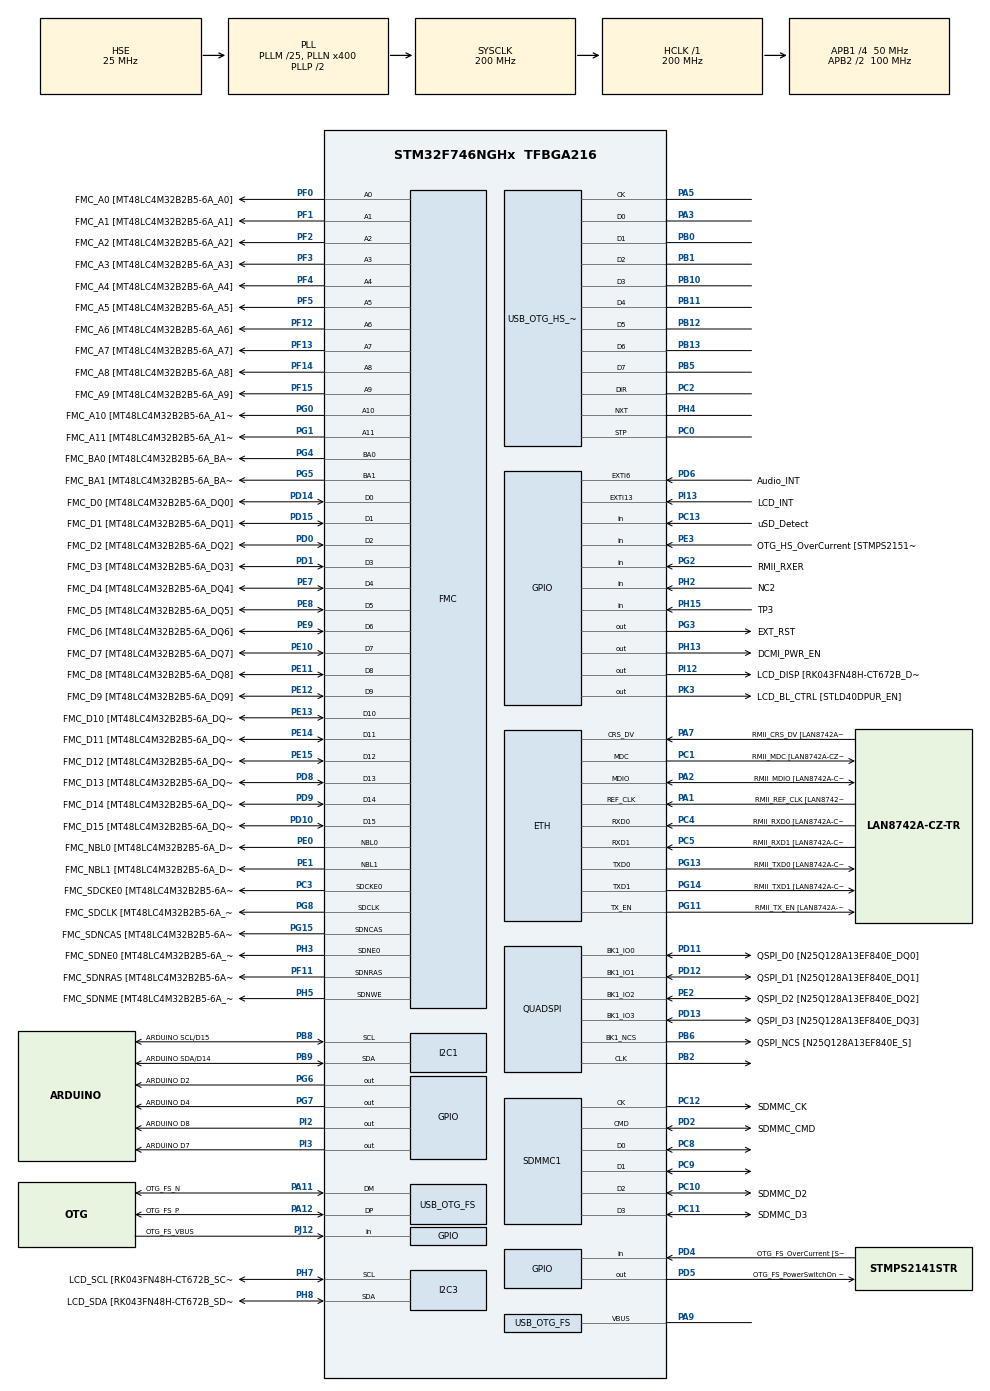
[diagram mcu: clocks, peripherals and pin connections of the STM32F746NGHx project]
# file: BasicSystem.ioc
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CORTEX_M7.ART_ACCLERATOR_ENABLE=1
CORTEX_M7.AccessPermission-Cortex_Memory_Protection_Unit_Region0_Settings=MPU_REGION_FULL_ACCESS
CORTEX_M7.AccessPermission-Cortex_Memory_Protection_Unit_Region1_Settings=MPU_REGION_FULL_ACCESS
CORTEX_M7.BaseAddress-Cortex_Memory_Protection_Unit_Region0_Settings=0x90000000
CORTEX_M7.BaseAddress-Cortex_Memory_Protection_Unit_Region1_Settings=0x90000000
CORTEX_M7.CPU_DCache=Enabled
CORTEX_M7.CPU_ICache=Enabled
CORTEX_M7.Enable-Cortex_Memory_Protection_Unit_Region0_Settings=MPU_REGION_ENABLE
CORTEX_M7.Enable-Cortex_Memory_Protection_Unit_Region1_Settings=MPU_REGION_ENABLE
CORTEX_M7.IsCacheable-Cortex_Memory_Protection_Unit_Region1_Settings=MPU_ACCESS_CACHEABLE
CORTEX_M7.MPU_Control=MPU_PRIVILEGED_DEFAULT
CORTEX_M7.PREFETCH_ENABLE=1
CORTEX_M7.Size-Cortex_Memory_Protection_Unit_Region0_Settings=MPU_REGION_SIZE_256MB
CORTEX_M7.Size-Cortex_Memory_Protection_Unit_Region1_Settings=MPU_REGION_SIZE_16MB
Dma.Request0=SDMMC1_RX
Dma.Request1=SDMMC1_TX
Dma.SDMMC1_RX.0.Direction=DMA_PERIPH_TO_MEMORY
Dma.SDMMC1_RX.0.FIFOMode=DMA_FIFOMODE_ENABLE
Dma.SDMMC1_RX.0.FIFOThreshold=DMA_FIFO_THRESHOLD_FULL
Dma.SDMMC1_RX.0.Instance=DMA2_Stream3
Dma.SDMMC1_RX.0.MemBurst=DMA_MBURST_INC4
Dma.SDMMC1_RX.0.MemDataAlignment=DMA_MDATAALIGN_WORD
Dma.SDMMC1_RX.0.MemInc=DMA_MINC_ENABLE
Dma.SDMMC1_RX.0.Mode=DMA_PFCTRL
Dma.SDMMC1_RX.0.PeriphBurst=DMA_PBURST_INC4
Dma.SDMMC1_RX.0.PeriphDataAlignment=DMA_PDATAALIGN_WORD
Dma.SDMMC1_RX.0.PeriphInc=DMA_PINC_DISABLE
Dma.SDMMC1_RX.0.Priority=DMA_PRIORITY_LOW
Dma.SDMMC1_TX.1.Direction=DMA_MEMORY_TO_PERIPH
Dma.SDMMC1_TX.1.FIFOMode=DMA_FIFOMODE_ENABLE
Dma.SDMMC1_TX.1.FIFOThreshold=DMA_FIFO_THRESHOLD_FULL
Dma.SDMMC1_TX.1.Instance=DMA2_Stream6
Dma.SDMMC1_TX.1.MemBurst=DMA_MBURST_INC4
Dma.SDMMC1_TX.1.MemDataAlignment=DMA_MDATAALIGN_WORD
Dma.SDMMC1_TX.1.MemInc=DMA_MINC_ENABLE
Dma.SDMMC1_TX.1.Mode=DMA_PFCTRL
Dma.SDMMC1_TX.1.PeriphBurst=DMA_PBURST_INC4
Dma.SDMMC1_TX.1.PeriphDataAlignment=DMA_PDATAALIGN_WORD
Dma.SDMMC1_TX.1.PeriphInc=DMA_PINC_DISABLE
Dma.SDMMC1_TX.1.Priority=DMA_PRIORITY_LOW
ETH.MediaInterface=ETH_MEDIA_INTERFACE_RMII
FATFS.BSP.number=1
FATFS0.BSP.STBoard=false
FATFS0.BSP.api=Unknown
FATFS0.BSP.i2caddr=0
FATFS0.BSP.instance=PC13
FATFS0.BSP.ip=GPIO
FATFS0.BSP.mode=Input
FATFS0.BSP.name=Detect_SDIO
FATFS0.BSP.solution=PC13
FMC.CASLatency1=FMC_SDRAM_CAS_LATENCY_3
FMC.ExitSelfRefreshDelay1=7
FMC.LoadToActiveDelay1=2
FMC.RCDDelay1=2
FMC.RPDelay1=2
FMC.RPDelay2=2
FMC.ReadBurst1=FMC_SDRAM_RBURST_ENABLE
FMC.ReadBurst2=FMC_SDRAM_RBURST_ENABLE
FMC.RowCycleDelay1=7
FMC.RowCycleDelay2=7
FMC.SDClockPeriod1=FMC_SDRAM_CLOCK_PERIOD_2
FMC.SDClockPeriod2=FMC_SDRAM_CLOCK_PERIOD_2
FMC.SelfRefreshTime1=4
FMC.WriteRecoveryTime1=3
FREERTOS.MEMORY_ALLOCATION=2
FREERTOS.Tasks01=defaultTaskHand,0,4096,StartDefaultTask,Default,NULL,Dynamic,NULL,NULL
FREERTOS.configCHECK_FOR_STACK_OVERFLOW=2
FREERTOS.configTOTAL_HEAP_SIZE=32768
FREERTOS.configUSE_APPLICATION_TASK_TAG=1
FREERTOS.configUSE_COUNTING_SEMAPHORES=1
FREERTOS.configUSE_IDLE_HOOK=1
FREERTOS.configUSE_MALLOC_FAILED_HOOK=1
FREERTOS.configUSE_RECURSIVE_MUTEXES=1
I2C1.Timing=0x00C0EAFF
I2C3.I2C_Rise_Time=0
I2C3.Speed=100
I2C3.Timing=0x00C0EAFF
LWIP.Version=v2.1.2_Cube
Mcu.Family=STM32F7
Mcu.Name=STM32F746NGHx
Mcu.Package=TFBGA216
NVIC.DMA2D_IRQn=true\:5\:0\:false\:false\:true\:true\:true\:true
NVIC.DMA2_Stream3_IRQn=true\:5\:0\:false\:false\:true\:true\:false\:true
NVIC.DMA2_Stream6_IRQn=true\:5\:0\:false\:false\:true\:true\:false\:true
NVIC.ETH_IRQn=true\:5\:0\:false\:false\:true\:true\:false\:true
NVIC.OTG_FS_IRQn=true\:5\:0\:false\:false\:true\:true\:false\:true
NVIC.OTG_HS_IRQn=true\:5\:0\:false\:false\:true\:true\:false\:true
NVIC.PriorityGroup=NVIC_PRIORITYGROUP_4
NVIC.SDMMC1_IRQn=true\:5\:0\:false\:false\:true\:true\:true\:true
NVIC.TIM6_DAC_IRQn=true\:0\:0\:false\:false\:true\:false\:false\:true
NVIC.TimeBase=TIM6_DAC_IRQn
NVIC.TimeBaseIP=TIM6
PA0/WKUP.GPIO_Label=ARDUINO A0
PA0/WKUP.GPIO_Mode=GPIO_MODE_ANALOG
PA0/WKUP.GPIO_PuPd=GPIO_NOPULL
PA0/WKUP.Signal=ADCx_IN0
PA1.GPIO_Label=RMII_REF_CLK [LAN8742A-CZ-TR_REFCLK0]
PA1.Mode=RMII
PA1.Signal=ETH_REF_CLK
PA10.GPIO_Label=OTG_FS_ID
PA10.Signal=USB_OTG_FS_ID
PA11.GPIO_Label=OTG_FS_N
PA11.GPIO_Speed=GPIO_SPEED_FREQ_VERY_HIGH
PA11.Mode=Host_Only
PA11.Signal=USB_OTG_FS_DM
PA12.GPIO_Label=OTG_FS_P
PA12.GPIO_Speed=GPIO_SPEED_FREQ_VERY_HIGH
PA12.Mode=Host_Only
PA12.Signal=USB_OTG_FS_DP
PA13.GPIO_Label=SWDIO
PA13.Mode=Serial_Wire
PA13.Signal=SYS_JTMS-SWDIO
PA14.GPIO_Label=SWCLK
PA14.Mode=Serial_Wire
PA14.Signal=SYS_JTCK-SWCLK
PA15.GPIO_Label=ARDUINO PWM/D9
PA15.GPIO_ModeDefaultPP=GPIO_MODE_AF_PP
PA15.GPIO_PuPd=GPIO_NOPULL
PA15.GPIO_Speed=GPIO_SPEED_FREQ_LOW
PA15.Signal=S_TIM2_CH1_ETR
PA2.GPIO_Label=RMII_MDIO [LAN8742A-CZ-TR_MDIO]
PA2.Mode=RMII
PA2.Signal=ETH_MDIO
PA3.GPIO_Mode=GPIO_MODE_AF_PP
PA3.GPIO_PuPd=GPIO_NOPULL
PA3.GPIO_Speed=GPIO_SPEED_FREQ_VERY_HIGH
PA3.Mode=Device_HS
PA3.Signal=USB_OTG_HS_ULPI_D0
PA4.GPIO_Label=DCMI_HSYNC
PA4.Signal=DCMI_HSYNC
PA5.GPIO_Mode=GPIO_MODE_AF_PP
PA5.GPIO_PuPd=GPIO_NOPULL
PA5.GPIO_Speed=GPIO_SPEED_FREQ_VERY_HIGH
PA5.Mode=Device_HS
PA5.Signal=USB_OTG_HS_ULPI_CK
PA6.Signal=DCMI_PIXCLK
PA7.GPIO_Label=RMII_CRS_DV [LAN8742A-CZ-TR_CRS_DV]
PA7.Mode=RMII
PA7.Signal=ETH_CRS_DV
PA8.GPIO_Label=ARDUINO PWM/D10
PA8.GPIO_ModeDefaultPP=GPIO_MODE_AF_PP
PA8.GPIO_PuPd=GPIO_NOPULL
PA8.GPIO_Speed=GPIO_SPEED_FREQ_LOW
PA8.Signal=S_TIM1_CH1
PA9.GPIO_PuPd=GPIO_NOPULL
PA9.Mode=Activate_VBUS
PA9.Signal=USB_OTG_FS_VBUS
PB0.GPIO_Mode=GPIO_MODE_AF_PP
PB0.GPIO_PuPd=GPIO_NOPULL
PB0.GPIO_Speed=GPIO_SPEED_FREQ_VERY_HIGH
PB0.Mode=Device_HS
PB0.Signal=USB_OTG_HS_ULPI_D1
PB1.GPIO_Mode=GPIO_MODE_AF_PP
PB1.GPIO_PuPd=GPIO_NOPULL
PB1.GPIO_Speed=GPIO_SPEED_FREQ_VERY_HIGH
PB1.Mode=Device_HS
PB1.Signal=USB_OTG_HS_ULPI_D2
PB10.GPIO_Mode=GPIO_MODE_AF_PP
PB10.GPIO_PuPd=GPIO_NOPULL
PB10.GPIO_Speed=GPIO_SPEED_FREQ_VERY_HIGH
PB10.Mode=Device_HS
PB10.Signal=USB_OTG_HS_ULPI_D3
PB11.GPIO_Mode=GPIO_MODE_AF_PP
PB11.GPIO_PuPd=GPIO_NOPULL
PB11.GPIO_Speed=GPIO_SPEED_FREQ_VERY_HIGH
PB11.Mode=Device_HS
PB11.Signal=USB_OTG_HS_ULPI_D4
PB12.GPIO_Mode=GPIO_MODE_AF_PP
PB12.GPIO_PuPd=GPIO_NOPULL
PB12.GPIO_Speed=GPIO_SPEED_FREQ_VERY_HIGH
PB12.Mode=Device_HS
PB12.Signal=USB_OTG_HS_ULPI_D5
PB13.GPIO_Mode=GPIO_MODE_AF_PP
PB13.GPIO_PuPd=GPIO_NOPULL
PB13.GPIO_Speed=GPIO_SPEED_FREQ_VERY_HIGH
PB13.Mode=Device_HS
PB13.Signal=USB_OTG_HS_ULPI_D6
PB14.GPIO_Label=ARDUINO MISO/D12
PB14.GPIO_Mode=GPIO_MODE_AF_PP
PB14.GPIO_PuPd=GPIO_NOPULL
PB14.GPIO_Speed=GPIO_SPEED_FREQ_LOW
PB14.Signal=SPI2_MISO
PB15.GPIO_Label=ARDUINO MOSI/PWM/D11
PB15.GPIO_Mode=GPIO_MODE_AF_PP
PB15.GPIO_PuPd=GPIO_NOPULL
PB15.GPIO_Speed=GPIO_SPEED_FREQ_LOW
PB15.Signal=SPI2_MOSI
PB2.Mode=Single Bank 1
PB2.Signal=QUADSPI_CLK
PB3.GPIO_Label=SWO
PB3.Signal=SYS_JTDO-SWO
PB4.GPIO_Label=ARDUINO PWM/D3
PB4.GPIO_ModeDefaultPP=GPIO_MODE_AF_PP
PB4.GPIO_PuPd=GPIO_NOPULL
PB4.GPIO_Speed=GPIO_SPEED_FREQ_LOW
PB4.Signal=S_TIM3_CH1
PB5.GPIO_Mode=GPIO_MODE_AF_PP
PB5.GPIO_PuPd=GPIO_NOPULL
PB5.GPIO_Speed=GPIO_SPEED_FREQ_VERY_HIGH
PB5.Mode=Device_HS
PB5.Signal=USB_OTG_HS_ULPI_D7
PB6.GPIO_Label=QSPI_NCS [N25Q128A13EF840E_S]
PB6.Mode=Single Bank 1
PB6.Signal=QUADSPI_BK1_NCS
PB7.GPIO_Label=VCP_RX [STM32F103CBT6_PA2]
PB7.GPIO_Mode=GPIO_MODE_AF_PP
PB7.GPIO_PuPd=GPIO_NOPULL
PB7.GPIO_Speed=GPIO_SPEED_FREQ_LOW
PB7.Signal=USART1_RX
PB8.GPIO_Label=ARDUINO SCL/D15
PB8.GPIO_Mode=GPIO_MODE_AF_OD
PB8.GPIO_Pu=GPIO_PULLUP
PB8.GPIO_PuPd=GPIO_NOPULL
PB8.GPIO_Speed=GPIO_SPEED_FREQ_LOW
PB8.Mode=I2C
PB8.Signal=I2C1_SCL
PB9.GPIO_Label=ARDUINO SDA/D14
PB9.GPIO_Mode=GPIO_MODE_AF_OD
PB9.GPIO_Pu=GPIO_PULLUP
PB9.GPIO_PuPd=GPIO_NOPULL
PB9.GPIO_Speed=GPIO_SPEED_FREQ_LOW
PB9.Mode=I2C
PB9.Signal=I2C1_SDA
PC0.GPIO_Mode=GPIO_MODE_AF_PP
PC0.GPIO_PuPd=GPIO_NOPULL
PC0.GPIO_Speed=GPIO_SPEED_FREQ_VERY_HIGH
PC0.Mode=Device_HS
PC0.Signal=USB_OTG_HS_ULPI_STP
PC1.GPIO_Label=RMII_MDC [LAN8742A-CZ-TR_MDC]
PC1.Mode=RMII
PC1.Signal=ETH_MDC
PC10.GPIO_Label=SDMMC_D2
PC10.GPIO_PuPd=GPIO_PULLUP
PC10.Mode=SD_4_bits_Wide_bus
PC10.Signal=SDMMC1_D2
PC11.GPIO_Label=SDMMC_D3
PC11.GPIO_PuPd=GPIO_PULLUP
PC11.Mode=SD_4_bits_Wide_bus
PC11.Signal=SDMMC1_D3
PC12.GPIO_Label=SDMMC_CK
PC12.Mode=SD_4_bits_Wide_bus
PC12.Signal=SDMMC1_CK
PC13.GPIO_Label=uSD_Detect
PC13.Signal=GPIO_Input
PC14/OSC32_IN.GPIO_Label=RCC_OSC32_IN
PC14/OSC32_IN.Signal=RCC_OSC32_IN
PC15/OSC32_OUT.GPIO_Label=RCC_OSC32_OUT
PC15/OSC32_OUT.Signal=RCC_OSC32_OUT
PC2.GPIO_Mode=GPIO_MODE_AF_PP
PC2.GPIO_PuPd=GPIO_NOPULL
PC2.GPIO_Speed=GPIO_SPEED_FREQ_VERY_HIGH
PC2.Mode=Device_HS
PC2.Signal=USB_OTG_HS_ULPI_DIR
PC3.GPIO_Label=FMC_SDCKE0 [MT48LC4M32B2B5-6A_CKE]
PC3.Mode=SdramChipSelect1_1
PC3.Signal=FMC_SDCKE0
PC4.GPIO_Label=RMII_RXD0 [LAN8742A-CZ-TR_RXD0]
PC4.Mode=RMII
PC4.Signal=ETH_RXD0
PC5.GPIO_Label=RMII_RXD1 [LAN8742A-CZ-TR_RXD1]
PC5.Mode=RMII
PC5.Signal=ETH_RXD1
PC6.GPIO_Label=ARDUINO TX/D1
PC6.Signal=USART6_TX
PC7.GPIO_Label=ARDUINO RX/D0
PC7.Signal=USART6_RX
PC8.GPIO_PuPd=GPIO_PULLUP
PC8.Mode=SD_4_bits_Wide_bus
PC8.Signal=SDMMC1_D0
PC9.GPIO_PuPd=GPIO_PULLUP
PC9.Mode=SD_4_bits_Wide_bus
PC9.Signal=SDMMC1_D1
PD0.GPIO_Label=FMC_D2 [MT48LC4M32B2B5-6A_DQ2]
PD0.Signal=FMC_D2_DA2
PD1.GPIO_Label=FMC_D3 [MT48LC4M32B2B5-6A_DQ3]
PD1.Signal=FMC_D3_DA3
PD10.GPIO_Label=FMC_D15 [MT48LC4M32B2B5-6A_DQ15]
PD10.Signal=FMC_D15_DA15
PD11.GPIO_Label=QSPI_D0 [N25Q128A13EF840E_DQ0]
PD11.Mode=Single Bank 1
PD11.Signal=QUADSPI_BK1_IO0
PD12.GPIO_Label=QSPI_D1 [N25Q128A13EF840E_DQ1]
PD12.Mode=Single Bank 1
PD12.Signal=QUADSPI_BK1_IO1
PD13.GPIO_Label=QSPI_D3 [N25Q128A13EF840E_DQ3]
PD13.Mode=Single Bank 1
PD13.Signal=QUADSPI_BK1_IO3
PD14.GPIO_Label=FMC_D0 [MT48LC4M32B2B5-6A_DQ0]
PD14.Signal=FMC_D0_DA0
PD15.GPIO_Label=FMC_D1 [MT48LC4M32B2B5-6A_DQ1]
PD15.Signal=FMC_D1_DA1
PD2.GPIO_Label=SDMMC_CMD
PD2.GPIO_PuPd=GPIO_PULLUP
PD2.Mode=SD_4_bits_Wide_bus
PD2.Signal=SDMMC1_CMD
PD3.GPIO_Label=DCMI_D5
PD3.Signal=DCMI_D5
PD4.GPIO_Label=OTG_FS_OverCurrent [STMPS2141STR_Fault]
PD4.Signal=GPIO_Input
PD5.GPIO_Label=OTG_FS_PowerSwitchOn [STMPS2141STR_EN]
PD5.PinState=GPIO_PIN_SET
PD5.Signal=GPIO_Output
PD6.GPIO_Label=Audio_INT
PD6.GPIO_ModeDefaultEXTI=GPIO_MODE_EVT_RISING
PD6.Signal=GPXTI6
PD7.GPIO_Label=SPDIF_RX0 [74LVC1G04SE_4]
PD7.Signal=SPDIFRX_IN0
PD8.GPIO_Label=FMC_D13 [MT48LC4M32B2B5-6A_DQ13]
PD8.Signal=FMC_D13_DA13
PD9.GPIO_Label=FMC_D14 [MT48LC4M32B2B5-6A_DQ14]
PD9.Signal=FMC_D14_DA14
PE0.GPIO_Label=FMC_NBL0 [MT48LC4M32B2B5-6A_DQM0]
PE0.Signal=FMC_NBL0
PE1.GPIO_Label=FMC_NBL1 [MT48LC4M32B2B5-6A_DQM1]
PE1.Signal=FMC_NBL1
PE10.GPIO_Label=FMC_D7 [MT48LC4M32B2B5-6A_DQ7]
PE10.Signal=FMC_D7_DA7
PE11.GPIO_Label=FMC_D8 [MT48LC4M32B2B5-6A_DQ8]
PE11.Signal=FMC_D8_DA8
PE12.GPIO_Label=FMC_D9 [MT48LC4M32B2B5-6A_DQ9]
PE12.Signal=FMC_D9_DA9
PE13.GPIO_Label=FMC_D10 [MT48LC4M32B2B5-6A_DQ10]
PE13.Signal=FMC_D10_DA10
PE14.GPIO_Label=FMC_D11 [MT48LC4M32B2B5-6A_DQ11]
PE14.Signal=FMC_D11_DA11
PE15.GPIO_Label=FMC_D12 [MT48LC4M32B2B5-6A_DQ12]
PE15.Signal=FMC_D12_DA12
PE2.GPIO_Label=QSPI_D2 [N25Q128A13EF840E_DQ2]
PE2.Mode=Single Bank 1
PE2.Signal=QUADSPI_BK1_IO2
PE3.GPIO_Label=OTG_HS_OverCurrent [STMPS2151STR_FAULT]
PE3.Signal=GPIO_Input
PE4.GPIO_Label=LCD_B0 [RK043FN48H-CT672B_B0]
PE4.Signal=LTDC_B0
PE5.GPIO_Label=DCMI_D6
PE5.Signal=DCMI_D6
PE6.GPIO_Label=DCMI_D7
PE6.Signal=DCMI_D7
PE7.GPIO_Label=FMC_D4 [MT48LC4M32B2B5-6A_DQ4]
PE7.Signal=FMC_D4_DA4
PE8.GPIO_Label=FMC_D5 [MT48LC4M32B2B5-6A_DQ5]
PE8.Signal=FMC_D5_DA5
PE9.GPIO_Label=FMC_D6 [MT48LC4M32B2B5-6A_DQ6]
PE9.Signal=FMC_D6_DA6
PF0.GPIO_Label=FMC_A0 [MT48LC4M32B2B5-6A_A0]
PF0.Signal=FMC_A0
PF1.GPIO_Label=FMC_A1 [MT48LC4M32B2B5-6A_A1]
PF1.Signal=FMC_A1
PF10.GPIO_Label=ARDUINO A1
PF10.GPIO_Mode=GPIO_MODE_ANALOG
PF10.GPIO_PuPd=GPIO_NOPULL
PF10.Signal=ADC3_IN8
PF11.GPIO_Label=FMC_SDNRAS [MT48LC4M32B2B5-6A_RAS]
PF11.Signal=FMC_SDNRAS
PF12.GPIO_Label=FMC_A6 [MT48LC4M32B2B5-6A_A6]
PF12.Signal=FMC_A6
PF13.GPIO_Label=FMC_A7 [MT48LC4M32B2B5-6A_A7]
PF13.Signal=FMC_A7
PF14.GPIO_Label=FMC_A8 [MT48LC4M32B2B5-6A_A8]
PF14.Signal=FMC_A8
PF15.GPIO_Label=FMC_A9 [MT48LC4M32B2B5-6A_A9]
PF15.Signal=FMC_A9
PF2.GPIO_Label=FMC_A2 [MT48LC4M32B2B5-6A_A2]
PF2.Signal=FMC_A2
PF3.GPIO_Label=FMC_A3 [MT48LC4M32B2B5-6A_A3]
PF3.Signal=FMC_A3
PF4.GPIO_Label=FMC_A4 [MT48LC4M32B2B5-6A_A4]
PF4.Signal=FMC_A4
PF5.GPIO_Label=FMC_A5 [MT48LC4M32B2B5-6A_A5]
PF5.Signal=FMC_A5
PF6.GPIO_Label=ARDUINO A5
PF6.GPIO_Mode=GPIO_MODE_ANALOG
PF6.GPIO_PuPd=GPIO_NOPULL
PF6.Signal=ADC3_IN4
PF7.GPIO_Label=ARDUINO A4
PF7.GPIO_Mode=GPIO_MODE_ANALOG
PF7.GPIO_PuPd=GPIO_NOPULL
PF7.Signal=ADC3_IN5
PF8.GPIO_Label=ARDUINO A3
PF8.GPIO_Mode=GPIO_MODE_ANALOG
PF8.GPIO_PuPd=GPIO_NOPULL
PF8.Signal=ADC3_IN6
PF9.GPIO_Label=ARDUINO A2
PF9.GPIO_Mode=GPIO_MODE_ANALOG
PF9.GPIO_PuPd=GPIO_NOPULL
PF9.Signal=ADC3_IN7
PG0.GPIO_Label=FMC_A10 [MT48LC4M32B2B5-6A_A10]
PG0.Signal=FMC_A10
PG1.GPIO_Label=FMC_A11 [MT48LC4M32B2B5-6A_A11]
PG1.Signal=FMC_A11
PG10.GPIO_Label=SAI2_SDB [WM8994ECS/R_ADCDAT1]
PG10.Signal=SAI2_SD_B
PG11.GPIO_Label=RMII_TX_EN [LAN8742A-CZ-TR_TXEN]
PG11.Mode=RMII
PG11.Signal=ETH_TX_EN
PG12.GPIO_Label=LCD_B4 [RK043FN48H-CT672B_B4]
PG12.Signal=LTDC_B4
PG13.GPIO_Label=RMII_TXD0 [LAN8742A-CZ-TR_TXD0]
PG13.Mode=RMII
PG13.Signal=ETH_TXD0
PG14.GPIO_Label=RMII_TXD1 [LAN8742A-CZ-TR_TXD1]
PG14.Mode=RMII
PG14.Signal=ETH_TXD1
PG15.GPIO_Label=FMC_SDNCAS [MT48LC4M32B2B5-6A_CAS]
PG15.Signal=FMC_SDNCAS
PG2.GPIO_Label=RMII_RXER
PG2.Signal=GPIO_Input
PG3.GPIO_Label=EXT_RST
PG3.Signal=GPIO_Output
PG4.GPIO_Label=FMC_BA0 [MT48LC4M32B2B5-6A_BA0]
PG4.Signal=FMC_A14_BA0
PG5.GPIO_Label=FMC_BA1 [MT48LC4M32B2B5-6A_BA1]
PG5.Signal=FMC_A15_BA1
PG6.GPIO_Label=ARDUINO D2
PG6.Signal=GPIO_Output
PG7.GPIO_Label=ARDUINO D4
PG7.Signal=GPIO_Output
PG8.GPIO_Label=FMC_SDCLK [MT48LC4M32B2B5-6A_CLK]
PG8.Signal=FMC_SDCLK
PG9.GPIO_Label=DCMI_VSYNC
PG9.Signal=DCMI_VSYNC
PH0/OSC_IN.GPIO_Label=OSC_25M [NZ2520SB-25.00M_OUT]
PH0/OSC_IN.Mode=HSE-External-Oscillator
PH0/OSC_IN.Signal=RCC_OSC_IN
PH1/OSC_OUT.Mode=HSE-External-Oscillator
PH1/OSC_OUT.Signal=RCC_OSC_OUT
PH10.GPIO_Label=DCMI_D1
PH10.Signal=DCMI_D1
PH11.GPIO_Label=DCMI_D2
PH11.Signal=DCMI_D2
PH12.GPIO_Label=DCMI_D3
PH12.Signal=DCMI_D3
PH13.GPIO_Label=DCMI_PWR_EN
PH13.Signal=GPIO_Output
PH14.GPIO_Label=DCMI_D4
PH14.Signal=DCMI_D4
PH15.GPIO_Label=TP3
PH15.Signal=GPIO_Input
PH2.GPIO_Label=NC2
PH2.Signal=GPIO_Input
PH3.GPIO_Label=FMC_SDNE0 [MT48LC4M32B2B5-6A_CS]
PH3.Mode=SdramChipSelect1_1
PH3.Signal=FMC_SDNE0
PH4.GPIO_Mode=GPIO_MODE_AF_PP
PH4.GPIO_PuPd=GPIO_NOPULL
PH4.GPIO_Speed=GPIO_SPEED_FREQ_VERY_HIGH
PH4.Mode=Device_HS
PH4.Signal=USB_OTG_HS_ULPI_NXT
PH5.GPIO_Label=FMC_SDNME [MT48LC4M32B2B5-6A_WE]
PH5.Signal=FMC_SDNWE
PH6.GPIO_Label=ARDUINO PWM/D6
PH6.Signal=S_TIM12_CH1
PH7.GPIO_Label=LCD_SCL [RK043FN48H-CT672B_SCL]
PH7.GPIO_Pu=GPIO_PULLUP
PH7.Mode=I2C
PH7.Signal=I2C3_SCL
PH8.GPIO_Label=LCD_SDA [RK043FN48H-CT672B_SDA]
PH8.GPIO_Pu=GPIO_PULLUP
PH8.Mode=I2C
PH8.Signal=I2C3_SDA
PH9.GPIO_Label=DCMI_D0
PH9.Signal=DCMI_D0
PI0.GPIO_Label=ARDUINO PWM/CS/D5
PI0.GPIO_ModeDefaultPP=GPIO_MODE_AF_PP
PI0.GPIO_PuPd=GPIO_NOPULL
PI0.GPIO_Speed=GPIO_SPEED_FREQ_LOW
PI0.Signal=S_TIM5_CH4
PI1.GPIO_Label=ARDUINO SCK/D13
PI1.GPIO_Mode=GPIO_MODE_AF_PP
PI1.GPIO_PuPd=GPIO_NOPULL
PI1.GPIO_Speed=GPIO_SPEED_FREQ_LOW
PI1.Signal=SPI2_SCK
PI10.GPIO_Label=LCD_HSYNC [RK043FN48H-CT672B_HSYNC]
PI10.Signal=LTDC_HSYNC
PI12.GPIO_Label=LCD_DISP [RK043FN48H-CT672B_DISP]
PI12.PinState=GPIO_PIN_SET
PI12.Signal=GPIO_Output
PI13.GPIO_Label=LCD_INT
PI13.GPIO_ModeDefaultEXTI=GPIO_MODE_EVT_RISING
PI13.Signal=GPXTI13
PI14.GPIO_Label=LCD_CLK [RK043FN48H-CT672B_CLK]
PI14.Signal=LTDC_CLK
PI15.GPIO_Label=LCD_R0 [RK043FN48H-CT672B_R0]
PI15.Signal=LTDC_R0
PI2.GPIO_Label=ARDUINO D8
PI2.Signal=GPIO_Output
PI3.GPIO_Label=ARDUINO D7
PI3.Signal=GPIO_Output
PI4.GPIO_Label=SAI2_MCLKA [WM8994ECS/R_MCLK1]
PI4.Signal=SAI2_MCLK_A
PI5.GPIO_Label=SAI2_SCKA [WM8994ECS/R_BCLK1]
PI5.Signal=SAI2_SCK_A
PI6.GPIO_Label=SAI2_SDA [WM8994ECS/R_DACDAT1]
PI6.Signal=SAI2_SD_A
PI7.GPIO_Label=SAI2_FSA [WM8994ECS/R_LRCLK1]
PI7.Signal=SAI2_FS_A
PI8.GPIO_Label=NC1 [TP2]
PI8.Signal=RTC_TS
PI9.GPIO_Label=LCD_VSYNC [RK043FN48H-CT672B_VSYNC]
PI9.Signal=LTDC_VSYNC
PJ0.GPIO_Label=LCD_R1 [RK043FN48H-CT672B_R1]
PJ0.Signal=LTDC_R1
PJ1.GPIO_Label=LCD_R2 [RK043FN48H-CT672B_R2]
PJ1.Signal=LTDC_R2
PJ10.GPIO_Label=LCD_G3 [RK043FN48H-CT672B_G3]
PJ10.Signal=LTDC_G3
PJ11.GPIO_Label=LCD_G4 [RK043FN48H-CT672B_G4]
PJ11.Signal=LTDC_G4
PJ12.GPIO_Label=OTG_FS_VBUS
PJ12.Signal=GPIO_Input
PJ13.GPIO_Label=LCD_B1 [RK043FN48H-CT672B_B1]
PJ13.Signal=LTDC_B1
PJ14.GPIO_Label=LCD_B2 [RK043FN48H-CT672B_B2]
PJ14.Signal=LTDC_B2
PJ15.GPIO_Label=LCD_B3 [RK043FN48H-CT672B_B3]
PJ15.Signal=LTDC_B3
PJ2.GPIO_Label=LCD_R3 [RK043FN48H-CT672B_R3]
PJ2.Signal=LTDC_R3
PJ3.GPIO_Label=LCD_R4 [RK043FN48H-CT672B_R4]
PJ3.Signal=LTDC_R4
PJ4.GPIO_Label=LCD_R5 [RK043FN48H-CT672B_R5]
PJ4.Signal=LTDC_R5
PJ5.GPIO_Label=LCD_R6 [RK043FN48H-CT672B_R6]
PJ5.Signal=LTDC_R6
PJ6.GPIO_Label=LCD_R7 [RK043FN48H-CT672B_R7]
PJ6.Signal=LTDC_R7
PJ7.GPIO_Label=LCD_G0 [RK043FN48H-CT672B_G0]
PJ7.Signal=LTDC_G0
PJ8.GPIO_Label=LCD_G1 [RK043FN48H-CT672B_G1]
PJ8.Signal=LTDC_G1
PJ9.GPIO_Label=LCD_G2 [RK043FN48H-CT672B_G2]
PJ9.Signal=LTDC_G2
PK0.GPIO_Label=LCD_G5 [RK043FN48H-CT672B_G5]
PK0.Signal=LTDC_G5
PK1.GPIO_Label=LCD_G6 [RK043FN48H-CT672B_G6]
PK1.Signal=LTDC_G6
PK2.GPIO_Label=LCD_G7 [RK043FN48H-CT672B_G7]
PK2.Signal=LTDC_G7
PK3.GPIO_Label=LCD_BL_CTRL [STLD40DPUR_EN]
PK3.GPIO_Speed=GPIO_SPEED_FREQ_LOW
PK3.PinState=GPIO_PIN_SET
PK3.Signal=GPIO_Output
PK4.GPIO_Label=LCD_B5 [RK043FN48H-CT672B_B5]
PK4.Signal=LTDC_B5
PK5.GPIO_Label=LCD_B6 [RK043FN48H-CT672B_B6]
PK5.Signal=LTDC_B6
PK6.GPIO_Label=LCD_B7 [RK043FN48H-CT672B_B7]
PK6.Signal=LTDC_B7
PK7.GPIO_Label=LCD_DE [RK043FN48H-CT672B_DE]
PK7.Signal=LTDC_DE
ProjectManager.HeapSize=0xA00
ProjectManager.StackSize=0xA00
ProjectManager.TargetToolchain=STM32CubeIDE
QUADSPI.ChipSelectHighTime=QSPI_CS_HIGH_TIME_6_CYCLE
QUADSPI.ClockPrescaler=1
QUADSPI.FifoThreshold=4
QUADSPI.FlashSize=24
QUADSPI.SampleShifting=QSPI_SAMPLE_SHIFTING_HALFCYCLE
RCC.AHBFreq_Value=200000000
RCC.APB1CLKDivider=RCC_HCLK_DIV4
RCC.APB1Freq_Value=50000000
RCC.APB1TimFreq_Value=100000000
RCC.APB2CLKDivider=RCC_HCLK_DIV2
RCC.APB2Freq_Value=100000000
RCC.APB2TimFreq_Value=200000000
RCC.CortexFreq_Value=200000000
RCC.HCLKFreq_Value=200000000
RCC.HSE_VALUE=25000000
RCC.HSI_VALUE=16000000
RCC.LSE_VALUE=32768
RCC.PLL48CLockSelection=RCC_CLK48SOURCE_PLLSAIP
RCC.PLLI2SN=100
RCC.PLLM=25
RCC.PLLN=400
RCC.PLLQ=9
RCC.PLLSAIP=RCC_PLLSAIP_DIV4
RCC.PLLSAIR=5
RCC.PLLSAIRDiv=RCC_PLLSAIDIVR_8
RCC.SDMMCClockSelection=RCC_SDMMC1CLKSOURCE_CLK48
RCC.SYSCLKFreq_VALUE=200000000
RCC.SYSCLKSource=RCC_SYSCLKSOURCE_PLLCLK
RCC.USBFreq_Value=48000000
RCC.VCOOutputFreq_Value=400000000
SH.ADCx_IN0.0=ADC3_IN0
SH.FMC_A0.0=FMC_A0,12b-sda1
SH.FMC_A1.0=FMC_A1,12b-sda1
SH.FMC_A10.0=FMC_A10,12b-sda1
SH.FMC_A11.0=FMC_A11,12b-sda1
SH.FMC_A14_BA0.0=FMC_BA0,FourSdramBanks1
SH.FMC_A15_BA1.0=FMC_BA1,FourSdramBanks1
SH.FMC_A2.0=FMC_A2,12b-sda1
SH.FMC_A3.0=FMC_A3,12b-sda1
SH.FMC_A4.0=FMC_A4,12b-sda1
SH.FMC_A5.0=FMC_A5,12b-sda1
SH.FMC_A6.0=FMC_A6,12b-sda1
SH.FMC_A7.0=FMC_A7,12b-sda1
SH.FMC_A8.0=FMC_A8,12b-sda1
SH.FMC_A9.0=FMC_A9,12b-sda1
SH.FMC_D0_DA0.0=FMC_D0,sd-16b-d1
SH.FMC_D10_DA10.0=FMC_D10,sd-16b-d1
SH.FMC_D11_DA11.0=FMC_D11,sd-16b-d1
SH.FMC_D12_DA12.0=FMC_D12,sd-16b-d1
SH.FMC_D13_DA13.0=FMC_D13,sd-16b-d1
SH.FMC_D14_DA14.0=FMC_D14,sd-16b-d1
SH.FMC_D15_DA15.0=FMC_D15,sd-16b-d1
SH.FMC_D1_DA1.0=FMC_D1,sd-16b-d1
SH.FMC_D2_DA2.0=FMC_D2,sd-16b-d1
SH.FMC_D3_DA3.0=FMC_D3,sd-16b-d1
SH.FMC_D4_DA4.0=FMC_D4,sd-16b-d1
SH.FMC_D5_DA5.0=FMC_D5,sd-16b-d1
SH.FMC_D6_DA6.0=FMC_D6,sd-16b-d1
SH.FMC_D7_DA7.0=FMC_D7,sd-16b-d1
SH.FMC_D8_DA8.0=FMC_D8,sd-16b-d1
SH.FMC_D9_DA9.0=FMC_D9,sd-16b-d1
SH.FMC_NBL0.0=FMC_NBL0,Sd2ByteEnable1
SH.FMC_NBL1.0=FMC_NBL1,Sd2ByteEnable1
SH.FMC_SDCLK.0=FMC_SDCLK,12b-sda1
SH.FMC_SDNCAS.0=FMC_SDNCAS,12b-sda1
SH.FMC_SDNRAS.0=FMC_SDNRAS,12b-sda1
SH.FMC_SDNWE.0=FMC_SDNWE,12b-sda1
SH.S_TIM12_CH1.0=TIM12_CH1
SH.S_TIM1_CH1.0=TIM1_CH1
SH.S_TIM2_CH1_ETR.0=TIM2_CH1
SH.S_TIM3_CH1.0=TIM3_CH1
SH.S_TIM5_CH4.0=TIM5_CH4
USB_DEVICE.CLASS_NAME_HS=MSC
USB_DEVICE.VirtualMode-MSC_HS=Msc
USB_DEVICE.VirtualModeHS=Msc_HS
USB_HOST.BSP.number=1
USB_HOST.USBH_HandleTypeDef-MSC_FS=hUsbHostFS
USB_HOST.VirtualModeFS=Msc
USB_HOST0.BSP.STBoard=false
USB_HOST0.BSP.api=Unknown
USB_HOST0.BSP.i2caddr=0
USB_HOST0.BSP.instance=PD5
USB_HOST0.BSP.ip=GPIO
USB_HOST0.BSP.mode=Output
USB_HOST0.BSP.name=Drive_VBUS_FS
USB_HOST0.BSP.solution=PD5
USB_OTG_FS.VirtualMode=Host_Only
USB_OTG_FS.phy_itface=HCD_PHY_EMBEDDED
USB_OTG_HS.DeviceSpeed-Device_HS=PCD_SPEED_FULL
USB_OTG_HS.VirtualMode-Device_HS=Device_HS
VP_CRC_VS_CRC.Mode=CRC_Activate
VP_DMA2D_VS_DMA2D.Mode=DMA2D_Activate
VP_FATFS_VS_SDIO.Mode=SDIO
VP_FREERTOS_VS_CMSIS_V1.Mode=CMSIS_V1
VP_LWIP_VS_Enabled.Mode=Enabled
VP_SYS_VS_tim6.Mode=TIM6
VP_USB_DEVICE_VS_USB_DEVICE_MSC_HS.Mode=MSC_HS
VP_USB_HOST_VS_USB_HOST_MSC_FS.Mode=MSC_FS
board=32F746GDISCOVERY

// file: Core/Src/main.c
/* USER CODE BEGIN Header */
/**
  ******************************************************************************
  * @file           : main.c
  * @brief          : Main program body
  ******************************************************************************
  * @attention
  *
  * <h2><center>&copy; Copyright (c) 2019 STMicroelectronics.
  * All rights reserved.</center></h2>
  *
  * This software component is licensed by ST under Ultimate Liberty license
  * SLA0044, the "License"; You may not use this file except in compliance with
  * the License. You may obtain a copy of the License at:
  *                             www.st.com/SLA0044
  *
  ******************************************************************************
  */
/* USER CODE END Header */
#include "main.h"
#include "cmsis_os.h"
#include "fatfs.h"
#include "lwip.h"
#include "lwip/apps/httpd.h"
#include "usb_device.h"
#include "usb_host.h"

/* USER CODE BEGIN Includes */
#include <stm32746g_discovery_qspi.h>
#include <stm32746g_discovery_lcd.h>
#include <stm32746g_discovery_ts.h>
#include "string.h"
#include "../../Menu/Menu.h"
#include "../../Views/SDView.h"
#include <stdlib.h>
#define IMG_NO_DATA
#include "../../Images/Inc/icon_M.h"
#include <stdbool.h>
#include <ScreenManager.h>
/* USER CODE END Includes */

/* USER CODE BEGIN PD */

#define SDRAM_TIMEOUT                            ((uint32_t)0xFFFF)
#define SDRAM_MODEREG_BURST_LENGTH_1             ((uint16_t)0x0000)
#define SDRAM_MODEREG_BURST_LENGTH_2             ((uint16_t)0x0001)
#define SDRAM_MODEREG_BURST_LENGTH_4             ((uint16_t)0x0002)
#define SDRAM_MODEREG_BURST_LENGTH_8             ((uint16_t)0x0004)
#define SDRAM_MODEREG_BURST_TYPE_SEQUENTIAL      ((uint16_t)0x0000)
#define SDRAM_MODEREG_BURST_TYPE_INTERLEAVED     ((uint16_t)0x0008)
#define SDRAM_MODEREG_CAS_LATENCY_2              ((uint16_t)0x0020)
#define SDRAM_MODEREG_CAS_LATENCY_3              ((uint16_t)0x0030)
#define SDRAM_MODEREG_OPERATING_MODE_STANDARD    ((uint16_t)0x0000)
#define SDRAM_MODEREG_WRITEBURST_MODE_PROGRAMMED ((uint16_t)0x0000)
#define SDRAM_MODEREG_WRITEBURST_MODE_SINGLE     ((uint16_t)0x0200)

/* USER CODE END PD */

CRC_HandleTypeDef hcrc;

extern struct netif gnetif;

DMA2D_HandleTypeDef hdma2d;

I2C_HandleTypeDef hi2c1;
I2C_HandleTypeDef hi2c3;

QSPI_HandleTypeDef hqspi;

SD_HandleTypeDef hsd1;
DMA_HandleTypeDef hdma_sdmmc1_rx;
DMA_HandleTypeDef hdma_sdmmc1_tx;

SDRAM_HandleTypeDef hsdram1;

osThreadId defaultTaskHandHandle;
/* USER CODE BEGIN PV */
QueueHandle_t tsQueue;

static FMC_SDRAM_CommandTypeDef Command;
static TS_StateTypeDef  TS_State;
bool HoldTouch;
bool MenuActive = true;
bool SDCardActive = false;
bool NetViewActive = false;

ScreenManager* screenManager;

uint8_t hr;
uint8_t mn;
uint8_t sc;
/* USER CODE END PV */

void SystemClock_Config(void);
void PeriphCommonClock_Config(void);
static void MPU_Config(void);
static void MX_GPIO_Init(void);
static void MX_DMA_Init(void);
static void MX_CRC_Init(void);
static void MX_QUADSPI_Init(void);
static void MX_DMA2D_Init(void);
static void MX_FMC_Init(void);
static void MX_I2C3_Init(void);
static void MX_I2C1_Init(void);
static void MX_SDMMC1_SD_Init(void);
void StartDefaultTask(void const * argument);

/* USER CODE BEGIN PFP */
static void BSP_Config(void);
static void TS_Init(void);
static void ReactOnTouch(void);
static void QSPI_Init(void);
void NetViewTouchDetected(uint16_t x, uint16_t y);
void ViewTouchDetected(uint16_t x, uint16_t y);
void ViewKeyInput(uint8_t key);
void ShowNetView(uint8_t* headerString);
/* USER CODE END PFP */

/* USER CODE BEGIN 0 */
void TS_Init(void)
{
	uint8_t  status = 0;
	status = BSP_TS_Init(BSP_LCD_GetXSize(), BSP_LCD_GetYSize());
	HoldTouch = false;

	if (status != TS_OK)
	{
		BSP_LCD_SetBackColor(LCD_COLOR_WHITE);
		BSP_LCD_SetTextColor(LCD_COLOR_RED);
		BSP_LCD_DisplayStringAtLine(5, (uint8_t *)"ERROR");
		BSP_LCD_DisplayStringAtLine(6, (uint8_t *)"Touchscreen cannot be initialized");
	}
}

void ReactOnTouch(void)
{
	TSDataStruct data;

	data.x = TS_State.touchX[0];
	data.y = TS_State.touchY[0];

	xQueueSend(tsQueue, &data, portMAX_DELAY); // Sende die Daten in die Queue
}

void ReactOnClick(uint16_t x ,uint16_t y)
{
	TSDataStruct data;
	data.x = x;
	data.y = y;

	xQueueSend(tsQueue, &data, portMAX_DELAY); // Sende die Daten in die Queue
}

void ReactOnKey(uint8_t key)
{
	//if(NetViewActive)
		//ViewKeyInput(key);
}

void SDCardView()
{
	MenuActive = false;
	NetViewActive = false;
	SDCardActive = true;
	ShowSDDirectories((uint8_t *)"SD Karte");
}

void NetView_View()
{
	MenuActive = false;
	SDCardActive = false;
	NetViewActive = true;
	ShowNetView((uint8_t *)"Network");
}

void OldMainMenu()
{
	MenuActive = true;
	SDCardActive = false;
	NetViewActive = false;
	RemoveAllMenuPoints();
	void (*networkview_ptr)() = &NetView_View;

	InitMenuPoints(3);
	AddMenuPoint(60, 150, 110, 40, LCD_COLOR_ST_MAGENTA2,networkview_ptr, (uint8_t *)"Netzwerk");
}

void BSP_Config(void)
{
	BSP_LCD_Init();
	BSP_LCD_LayerDefaultInit(0, LCD_FB_START_ADDRESS);
	BSP_LCD_LayerDefaultInit(1, LCD_FB_START_ADDRESS+(4*(BSP_LCD_GetXSize()*BSP_LCD_GetYSize())));
	BSP_LCD_SelectLayer(0);
	BSP_LCD_Clear(LCD_COLOR_TRANSPARENT);
	BSP_LCD_SetBackColor(LCD_COLOR_TRANSPARENT);
	BSP_LCD_SelectLayer(1);

	screenManager = create_ScreenManager();
}

void QSPI_Init(void)
{
	//BSP_QSPI_Init();
	//BSP_QSPI_MemoryMappedMode();

	//WRITE_REG(QUADSPI->LPTR, 0xFFF);
}

/* USER CODE END 0 */

int main(void)
{

  /* MPU Configuration--------------------------------------------------------*/
  MPU_Config();

  /* Enable I-Cache---------------------------------------------------------*/
  SCB_EnableICache();

  /* Enable D-Cache---------------------------------------------------------*/
  SCB_EnableDCache();

  /* MCU Configuration--------------------------------------------------------*/

  /* Reset of all peripherals, Initializes the Flash interface and the Systick. */
  HAL_Init();

  /* Configure the system clock */
  SystemClock_Config();

/* Configure the peripherals common clocks */
  PeriphCommonClock_Config();

  /* USER CODE BEGIN SysInit */

  if (BSP_QSPI_Init() == HAL_OK)
  {
    BSP_QSPI_MemoryMappedMode();

    /* Configure QSPI: LPTR register with the low-power time out value */
    WRITE_REG(QUADSPI->LPTR, 0xFFF);
  }

  /* USER CODE END SysInit */

  /* Initialize all configured peripherals */
  MX_GPIO_Init();
  MX_DMA_Init();
  MX_CRC_Init();
  MX_QUADSPI_Init();
  MX_DMA2D_Init();
  MX_FMC_Init();
  MX_I2C3_Init();
  MX_I2C1_Init();
  MX_SDMMC1_SD_Init();
  MX_FATFS_Init();

  /* USER CODE BEGIN 2 */
  tsQueue = xQueueCreate(1, sizeof(TSDataStruct));  // Erstelle die Queue
  if (tsQueue == NULL)
  {
      // Fehlerbehandlung bei der Queue-Erstellung
  }
  /* USER CODE END 2 */

  /* Create the thread(s) */
  /* definition and creation of defaultTaskHand */
  osThreadDef(defaultTaskHand, StartDefaultTask, osPriorityNormal, 0, 4096);
  defaultTaskHandHandle = osThreadCreate(osThread(defaultTaskHand), NULL);

  /* Start scheduler */
  osKernelStart();
  /* USER CODE BEGIN 2 */

    httpd_init();

    /* USER CODE END 2 */

    /* Infinite loop */
    while (1)
    {

    }
}

void SystemClock_Config(void)
{
  RCC_OscInitTypeDef RCC_OscInitStruct = {0};
  RCC_ClkInitTypeDef RCC_ClkInitStruct = {0};

  /** Configure the main internal regulator output voltage
  */
  __HAL_RCC_PWR_CLK_ENABLE();
  __HAL_PWR_VOLTAGESCALING_CONFIG(PWR_REGULATOR_VOLTAGE_SCALE1);
  /** Initializes the RCC Oscillators according to the specified parameters
  * in the RCC_OscInitTypeDef structure.
  */
  RCC_OscInitStruct.OscillatorType = RCC_OSCILLATORTYPE_HSE;
  RCC_OscInitStruct.HSEState = RCC_HSE_ON;
  RCC_OscInitStruct.PLL.PLLState = RCC_PLL_ON;
  RCC_OscInitStruct.PLL.PLLSource = RCC_PLLSOURCE_HSE;
  RCC_OscInitStruct.PLL.PLLM = 25;
  RCC_OscInitStruct.PLL.PLLN = 400;
  RCC_OscInitStruct.PLL.PLLP = RCC_PLLP_DIV2;
  RCC_OscInitStruct.PLL.PLLQ = 9;
  if (HAL_RCC_OscConfig(&RCC_OscInitStruct) != HAL_OK)
  {
    Error_Handler();
  }
  /** Activate the Over-Drive mode
  */
  if (HAL_PWREx_EnableOverDrive() != HAL_OK)
  {
    Error_Handler();
  }
  /** Initializes the CPU, AHB and APB buses clocks
  */
  RCC_ClkInitStruct.ClockType = RCC_CLOCKTYPE_HCLK|RCC_CLOCKTYPE_SYSCLK
                              |RCC_CLOCKTYPE_PCLK1|RCC_CLOCKTYPE_PCLK2;
  RCC_ClkInitStruct.SYSCLKSource = RCC_SYSCLKSOURCE_PLLCLK;
  RCC_ClkInitStruct.AHBCLKDivider = RCC_SYSCLK_DIV1;
  RCC_ClkInitStruct.APB1CLKDivider = RCC_HCLK_DIV4;
  RCC_ClkInitStruct.APB2CLKDivider = RCC_HCLK_DIV2;

  if (HAL_RCC_ClockConfig(&RCC_ClkInitStruct, FLASH_LATENCY_6) != HAL_OK)
  {
    Error_Handler();
  }
}

void PeriphCommonClock_Config(void)
{
  RCC_PeriphCLKInitTypeDef PeriphClkInitStruct = {0};

  /** Initializes the peripherals clock
  */
  PeriphClkInitStruct.PeriphClockSelection = RCC_PERIPHCLK_SDMMC1|RCC_PERIPHCLK_CLK48;
  PeriphClkInitStruct.PLLSAI.PLLSAIN = 192;
  PeriphClkInitStruct.PLLSAI.PLLSAIR = 5;
  PeriphClkInitStruct.PLLSAI.PLLSAIQ = 2;
  PeriphClkInitStruct.PLLSAI.PLLSAIP = RCC_PLLSAIP_DIV4;
  PeriphClkInitStruct.PLLSAIDivQ = 1;
  PeriphClkInitStruct.PLLSAIDivR = RCC_PLLSAIDIVR_8;
  PeriphClkInitStruct.Clk48ClockSelection = RCC_CLK48SOURCE_PLLSAIP;
  PeriphClkInitStruct.Sdmmc1ClockSelection = RCC_SDMMC1CLKSOURCE_CLK48;
  if (HAL_RCCEx_PeriphCLKConfig(&PeriphClkInitStruct) != HAL_OK)
  {
    Error_Handler();
  }
}

static void MX_CRC_Init(void)
{

  hcrc.Instance = CRC;
  hcrc.Init.DefaultPolynomialUse = DEFAULT_POLYNOMIAL_ENABLE;
  hcrc.Init.DefaultInitValueUse = DEFAULT_INIT_VALUE_ENABLE;
  hcrc.Init.InputDataInversionMode = CRC_INPUTDATA_INVERSION_NONE;
  hcrc.Init.OutputDataInversionMode = CRC_OUTPUTDATA_INVERSION_DISABLE;
  hcrc.InputDataFormat = CRC_INPUTDATA_FORMAT_BYTES;
  if (HAL_CRC_Init(&hcrc) != HAL_OK)
  {
    Error_Handler();
  }

}

static void MX_DMA2D_Init(void)
{

  hdma2d.Instance = DMA2D;
  hdma2d.Init.Mode = DMA2D_M2M;
  hdma2d.Init.ColorMode = DMA2D_OUTPUT_ARGB8888;
  hdma2d.Init.OutputOffset = 0;
  hdma2d.LayerCfg[1].InputOffset = 0;
  hdma2d.LayerCfg[1].InputColorMode = DMA2D_INPUT_ARGB8888;
  hdma2d.LayerCfg[1].AlphaMode = DMA2D_NO_MODIF_ALPHA;
  hdma2d.LayerCfg[1].InputAlpha = 0;
  if (HAL_DMA2D_Init(&hdma2d) != HAL_OK)
  {
    Error_Handler();
  }
  if (HAL_DMA2D_ConfigLayer(&hdma2d, 1) != HAL_OK)
  {
    Error_Handler();
  }

}

static void MX_I2C1_Init(void)
{

  hi2c1.Instance = I2C1;
  hi2c1.Init.Timing = 0x00C0EAFF;
  hi2c1.Init.OwnAddress1 = 0;
  hi2c1.Init.AddressingMode = I2C_ADDRESSINGMODE_7BIT;
  hi2c1.Init.DualAddressMode = I2C_DUALADDRESS_DISABLE;
  hi2c1.Init.OwnAddress2 = 0;
  hi2c1.Init.OwnAddress2Masks = I2C_OA2_NOMASK;
  hi2c1.Init.GeneralCallMode = I2C_GENERALCALL_DISABLE;
  hi2c1.Init.NoStretchMode = I2C_NOSTRETCH_DISABLE;
  if (HAL_I2C_Init(&hi2c1) != HAL_OK)
  {
    Error_Handler();
  }
  /** Configure Analogue filter
  */
  if (HAL_I2CEx_ConfigAnalogFilter(&hi2c1, I2C_ANALOGFILTER_ENABLE) != HAL_OK)
  {
    Error_Handler();
  }
  /** Configure Digital filter
  */
  if (HAL_I2CEx_ConfigDigitalFilter(&hi2c1, 0) != HAL_OK)
  {
    Error_Handler();
  }

}

static void MX_I2C3_Init(void)
{

  hi2c3.Instance = I2C3;
  hi2c3.Init.Timing = 0x00C0EAFF;
  hi2c3.Init.OwnAddress1 = 0;
  hi2c3.Init.AddressingMode = I2C_ADDRESSINGMODE_7BIT;
  hi2c3.Init.DualAddressMode = I2C_DUALADDRESS_DISABLE;
  hi2c3.Init.OwnAddress2 = 0;
  hi2c3.Init.OwnAddress2Masks = I2C_OA2_NOMASK;
  hi2c3.Init.GeneralCallMode = I2C_GENERALCALL_DISABLE;
  hi2c3.Init.NoStretchMode = I2C_NOSTRETCH_DISABLE;
  if (HAL_I2C_Init(&hi2c3) != HAL_OK)
  {
    Error_Handler();
  }
  /** Configure Analogue filter
  */
  if (HAL_I2CEx_ConfigAnalogFilter(&hi2c3, I2C_ANALOGFILTER_ENABLE) != HAL_OK)
  {
    Error_Handler();
  }
  /** Configure Digital filter
  */
  if (HAL_I2CEx_ConfigDigitalFilter(&hi2c3, 0) != HAL_OK)
  {
    Error_Handler();
  }

}

static void MX_QUADSPI_Init(void)
{

  /* QUADSPI parameter configuration*/
  hqspi.Instance = QUADSPI;
  hqspi.Init.ClockPrescaler = 1;
  hqspi.Init.FifoThreshold = 4;
  hqspi.Init.SampleShifting = QSPI_SAMPLE_SHIFTING_HALFCYCLE;
  hqspi.Init.FlashSize = 24;
  hqspi.Init.ChipSelectHighTime = QSPI_CS_HIGH_TIME_6_CYCLE;
  hqspi.Init.ClockMode = QSPI_CLOCK_MODE_0;
  hqspi.Init.FlashID = QSPI_FLASH_ID_1;
  hqspi.Init.DualFlash = QSPI_DUALFLASH_DISABLE;
  if (HAL_QSPI_Init(&hqspi) != HAL_OK)
  {
    Error_Handler();
  }

}

static void MX_SDMMC1_SD_Init(void)
{

  hsd1.Instance = SDMMC1;
  hsd1.Init.ClockEdge = SDMMC_CLOCK_EDGE_RISING;
  hsd1.Init.ClockBypass = SDMMC_CLOCK_BYPASS_DISABLE;
  hsd1.Init.ClockPowerSave = SDMMC_CLOCK_POWER_SAVE_DISABLE;
  hsd1.Init.BusWide = SDMMC_BUS_WIDE_1B;
  hsd1.Init.HardwareFlowControl = SDMMC_HARDWARE_FLOW_CONTROL_DISABLE;
  hsd1.Init.ClockDiv = 5;

}

static void MX_DMA_Init(void)
{

  /* DMA controller clock enable */
  __HAL_RCC_DMA2_CLK_ENABLE();

  /* DMA interrupt init */
  /* DMA2_Stream3_IRQn interrupt configuration */
  HAL_NVIC_SetPriority(DMA2_Stream3_IRQn, 5, 0);
  HAL_NVIC_EnableIRQ(DMA2_Stream3_IRQn);
  /* DMA2_Stream6_IRQn interrupt configuration */
  HAL_NVIC_SetPriority(DMA2_Stream6_IRQn, 5, 0);
  HAL_NVIC_EnableIRQ(DMA2_Stream6_IRQn);

}

/* FMC initialization function */
static void MX_FMC_Init(void)
{

  FMC_SDRAM_TimingTypeDef SdramTiming = {0};

  /** Perform the SDRAM1 memory initialization sequence
  */
  hsdram1.Instance = FMC_SDRAM_DEVICE;
  /* hsdram1.Init */
  hsdram1.Init.SDBank = FMC_SDRAM_BANK1;
  hsdram1.Init.ColumnBitsNumber = FMC_SDRAM_COLUMN_BITS_NUM_8;
  hsdram1.Init.RowBitsNumber = FMC_SDRAM_ROW_BITS_NUM_12;
  hsdram1.Init.MemoryDataWidth = FMC_SDRAM_MEM_BUS_WIDTH_16;
  hsdram1.Init.InternalBankNumber = FMC_SDRAM_INTERN_BANKS_NUM_4;
  hsdram1.Init.CASLatency = FMC_SDRAM_CAS_LATENCY_3;
  hsdram1.Init.WriteProtection = FMC_SDRAM_WRITE_PROTECTION_DISABLE;
  hsdram1.Init.SDClockPeriod = FMC_SDRAM_CLOCK_PERIOD_2;
  hsdram1.Init.ReadBurst = FMC_SDRAM_RBURST_ENABLE;
  hsdram1.Init.ReadPipeDelay = FMC_SDRAM_RPIPE_DELAY_0;
  /* SdramTiming */
  SdramTiming.LoadToActiveDelay = 2;
  SdramTiming.ExitSelfRefreshDelay = 7;
  SdramTiming.SelfRefreshTime = 4;
  SdramTiming.RowCycleDelay = 7;
  SdramTiming.WriteRecoveryTime = 3;
  SdramTiming.RPDelay = 2;
  SdramTiming.RCDDelay = 2;

  if (HAL_SDRAM_Init(&hsdram1, &SdramTiming) != HAL_OK)
  {
    Error_Handler( );
  }

  /* USER CODE BEGIN FMC_Init 2 */
    __IO uint32_t tmpmrd = 0;

    /* Step 1: Configure a clock configuration enable command */
    Command.CommandMode            = FMC_SDRAM_CMD_CLK_ENABLE;
    Command.CommandTarget          =  FMC_SDRAM_CMD_TARGET_BANK1;
    Command.AutoRefreshNumber      = 1;
    Command.ModeRegisterDefinition = 0;

    /* Send the command */
    HAL_SDRAM_SendCommand(&hsdram1, &Command, SDRAM_TIMEOUT);

    /* Step 2: Insert 100 us minimum delay */
    /* Inserted delay is equal to 1 ms due to systick time base unit (ms) */
    HAL_Delay(1);

    /* Step 3: Configure a PALL (precharge all) command */
    Command.CommandMode            = FMC_SDRAM_CMD_PALL;
    Command.CommandTarget          = FMC_SDRAM_CMD_TARGET_BANK1;
    Command.AutoRefreshNumber      = 1;
    Command.ModeRegisterDefinition = 0;

    /* Send the command */
    HAL_SDRAM_SendCommand(&hsdram1, &Command, SDRAM_TIMEOUT);

    /* Step 4: Configure an Auto Refresh command */
    Command.CommandMode            = FMC_SDRAM_CMD_AUTOREFRESH_MODE;
    Command.CommandTarget          = FMC_SDRAM_CMD_TARGET_BANK1;
    Command.AutoRefreshNumber      = 8;
    Command.ModeRegisterDefinition = 0;

    /* Send the command */
    HAL_SDRAM_SendCommand(&hsdram1, &Command, SDRAM_TIMEOUT);

    /* Step 5: Program the external memory mode register */
    tmpmrd = (uint32_t)SDRAM_MODEREG_BURST_LENGTH_1 | \
             SDRAM_MODEREG_BURST_TYPE_SEQUENTIAL    | \
             SDRAM_MODEREG_CAS_LATENCY_3            | \
             SDRAM_MODEREG_OPERATING_MODE_STANDARD  | \
             SDRAM_MODEREG_WRITEBURST_MODE_SINGLE;

    Command.CommandMode            = FMC_SDRAM_CMD_LOAD_MODE;
    Command.CommandTarget          = FMC_SDRAM_CMD_TARGET_BANK1;
    Command.AutoRefreshNumber      = 1;
    Command.ModeRegisterDefinition = tmpmrd;

    /* Send the command */
    HAL_SDRAM_SendCommand(&hsdram1, &Command, SDRAM_TIMEOUT);

    /* Step 6: Set the refresh rate counter */
    /* Set the device refresh rate */
    HAL_SDRAM_ProgramRefreshRate(&hsdram1, REFRESH_COUNT);

    //Deactivate speculative/cache access to first FMC Bank to save FMC bandwidth
    FMC_Bank1->BTCR[0] = 0x000030D2;
  /* USER CODE END FMC_Init 2 */
}

static void MX_GPIO_Init(void)
{
  GPIO_InitTypeDef GPIO_InitStruct = {0};

  /* GPIO Ports Clock Enable */
  __HAL_RCC_GPIOE_CLK_ENABLE();
  __HAL_RCC_GPIOG_CLK_ENABLE();
  __HAL_RCC_GPIOB_CLK_ENABLE();
  __HAL_RCC_GPIOD_CLK_ENABLE();
  __HAL_RCC_GPIOC_CLK_ENABLE();
  __HAL_RCC_GPIOA_CLK_ENABLE();
  __HAL_RCC_GPIOJ_CLK_ENABLE();
  __HAL_RCC_GPIOI_CLK_ENABLE();
  __HAL_RCC_GPIOK_CLK_ENABLE();
  __HAL_RCC_GPIOF_CLK_ENABLE();
  __HAL_RCC_GPIOH_CLK_ENABLE();

  /*Configure GPIO pin Output Level */
  HAL_GPIO_WritePin(OTG_FS_PowerSwitchOn_GPIO_Port, OTG_FS_PowerSwitchOn_Pin, GPIO_PIN_SET);

  /*Configure GPIO pin Output Level */
  HAL_GPIO_WritePin(GPIOI, ARDUINO_D7_Pin|ARDUINO_D8_Pin, GPIO_PIN_RESET);

  /*Configure GPIO pin Output Level */
  HAL_GPIO_WritePin(LCD_BL_CTRL_GPIO_Port, LCD_BL_CTRL_Pin, GPIO_PIN_SET);

  /*Configure GPIO pin Output Level */
  HAL_GPIO_WritePin(LCD_DISP_GPIO_Port, LCD_DISP_Pin, GPIO_PIN_SET);

  /*Configure GPIO pin Output Level */
  HAL_GPIO_WritePin(DCMI_PWR_EN_GPIO_Port, DCMI_PWR_EN_Pin, GPIO_PIN_RESET);

  /*Configure GPIO pin Output Level */
  HAL_GPIO_WritePin(GPIOG, ARDUINO_D4_Pin|ARDUINO_D2_Pin|EXT_RST_Pin, GPIO_PIN_RESET);

  /*Configure GPIO pin : LCD_B0_Pin */
  GPIO_InitStruct.Pin = LCD_B0_Pin;
  GPIO_InitStruct.Mode = GPIO_MODE_AF_PP;
  GPIO_InitStruct.Pull = GPIO_NOPULL;
  GPIO_InitStruct.Speed = GPIO_SPEED_FREQ_LOW;
  GPIO_InitStruct.Alternate = GPIO_AF14_LTDC;
  HAL_GPIO_Init(LCD_B0_GPIO_Port, &GPIO_InitStruct);

  /*Configure GPIO pin : OTG_HS_OverCurrent_Pin */
  GPIO_InitStruct.Pin = OTG_HS_OverCurrent_Pin;
  GPIO_InitStruct.Mode = GPIO_MODE_INPUT;
  GPIO_InitStruct.Pull = GPIO_NOPULL;
  HAL_GPIO_Init(OTG_HS_OverCurrent_GPIO_Port, &GPIO_InitStruct);

  /*Configure GPIO pin : ARDUINO_PWM_D3_Pin */
  GPIO_InitStruct.Pin = ARDUINO_PWM_D3_Pin;
  GPIO_InitStruct.Mode = GPIO_MODE_AF_PP;
  GPIO_InitStruct.Pull = GPIO_NOPULL;
  GPIO_InitStruct.Speed = GPIO_SPEED_FREQ_LOW;
  GPIO_InitStruct.Alternate = GPIO_AF2_TIM3;
  HAL_GPIO_Init(ARDUINO_PWM_D3_GPIO_Port, &GPIO_InitStruct);

  /*Configure GPIO pin : SPDIF_RX0_Pin */
  GPIO_InitStruct.Pin = SPDIF_RX0_Pin;
  GPIO_InitStruct.Mode = GPIO_MODE_AF_PP;
  GPIO_InitStruct.Pull = GPIO_NOPULL;
  GPIO_InitStruct.Speed = GPIO_SPEED_FREQ_LOW;
  GPIO_InitStruct.Alternate = GPIO_AF8_SPDIFRX;
  HAL_GPIO_Init(SPDIF_RX0_GPIO_Port, &GPIO_InitStruct);

  /*Configure GPIO pin : ARDUINO_PWM_D9_Pin */
  GPIO_InitStruct.Pin = ARDUINO_PWM_D9_Pin;
  GPIO_InitStruct.Mode = GPIO_MODE_AF_PP;
  GPIO_InitStruct.Pull = GPIO_NOPULL;
  GPIO_InitStruct.Speed = GPIO_SPEED_FREQ_LOW;
  GPIO_InitStruct.Alternate = GPIO_AF1_TIM2;
  HAL_GPIO_Init(ARDUINO_PWM_D9_GPIO_Port, &GPIO_InitStruct);

  /*Configure GPIO pins : DCMI_D6_Pin DCMI_D7_Pin */
  GPIO_InitStruct.Pin = DCMI_D6_Pin|DCMI_D7_Pin;
  GPIO_InitStruct.Mode = GPIO_MODE_AF_PP;
  GPIO_InitStruct.Pull = GPIO_NOPULL;
  GPIO_InitStruct.Speed = GPIO_SPEED_FREQ_LOW;
  GPIO_InitStruct.Alternate = GPIO_AF13_DCMI;
  HAL_GPIO_Init(GPIOE, &GPIO_InitStruct);

  /*Configure GPIO pin : VCP_RX_Pin */
  GPIO_InitStruct.Pin = VCP_RX_Pin;
  GPIO_InitStruct.Mode = GPIO_MODE_AF_PP;
  GPIO_InitStruct.Pull = GPIO_NOPULL;
  GPIO_InitStruct.Speed = GPIO_SPEED_FREQ_LOW;
  GPIO_InitStruct.Alternate = GPIO_AF7_USART1;
  HAL_GPIO_Init(VCP_RX_GPIO_Port, &GPIO_InitStruct);

  /*Configure GPIO pins : LCD_B1_Pin LCD_B2_Pin LCD_B3_Pin LCD_G4_Pin
                           LCD_G1_Pin LCD_G3_Pin LCD_G0_Pin LCD_G2_Pin
                           LCD_R7_Pin LCD_R5_Pin LCD_R6_Pin LCD_R4_Pin
                           LCD_R3_Pin LCD_R1_Pin LCD_R2_Pin */
  GPIO_InitStruct.Pin = LCD_B1_Pin|LCD_B2_Pin|LCD_B3_Pin|LCD_G4_Pin
                          |LCD_G1_Pin|LCD_G3_Pin|LCD_G0_Pin|LCD_G2_Pin
                          |LCD_R7_Pin|LCD_R5_Pin|LCD_R6_Pin|LCD_R4_Pin
                          |LCD_R3_Pin|LCD_R1_Pin|LCD_R2_Pin;
  GPIO_InitStruct.Mode = GPIO_MODE_AF_PP;
  GPIO_InitStruct.Pull = GPIO_NOPULL;
  GPIO_InitStruct.Speed = GPIO_SPEED_FREQ_LOW;
  GPIO_InitStruct.Alternate = GPIO_AF14_LTDC;
  HAL_GPIO_Init(GPIOJ, &GPIO_InitStruct);

  /*Configure GPIO pin : OTG_FS_VBUS_Pin */
  GPIO_InitStruct.Pin = OTG_FS_VBUS_Pin;
  GPIO_InitStruct.Mode = GPIO_MODE_INPUT;
  GPIO_InitStruct.Pull = GPIO_NOPULL;
  HAL_GPIO_Init(OTG_FS_VBUS_GPIO_Port, &GPIO_InitStruct);

  /*Configure GPIO pin : Audio_INT_Pin */
  GPIO_InitStruct.Pin = Audio_INT_Pin;
  GPIO_InitStruct.Mode = GPIO_MODE_EVT_RISING;
  GPIO_InitStruct.Pull = GPIO_NOPULL;
  HAL_GPIO_Init(Audio_INT_GPIO_Port, &GPIO_InitStruct);

  /*Configure GPIO pins : SAI2_MCLKA_Pin SAI2_SCKA_Pin SAI2_FSA_Pin SAI2_SDA_Pin */
  GPIO_InitStruct.Pin = SAI2_MCLKA_Pin|SAI2_SCKA_Pin|SAI2_FSA_Pin|SAI2_SDA_Pin;
  GPIO_InitStruct.Mode = GPIO_MODE_AF_PP;
  GPIO_InitStruct.Pull = GPIO_NOPULL;
  GPIO_InitStruct.Speed = GPIO_SPEED_FREQ_LOW;
  GPIO_InitStruct.Alternate = GPIO_AF10_SAI2;
  HAL_GPIO_Init(GPIOI, &GPIO_InitStruct);

  /*Configure GPIO pins : LCD_DE_Pin LCD_B7_Pin LCD_B6_Pin LCD_B5_Pin
                           LCD_G6_Pin LCD_G7_Pin LCD_G5_Pin */
  GPIO_InitStruct.Pin = LCD_DE_Pin|LCD_B7_Pin|LCD_B6_Pin|LCD_B5_Pin
                          |LCD_G6_Pin|LCD_G7_Pin|LCD_G5_Pin;
  GPIO_InitStruct.Mode = GPIO_MODE_AF_PP;
  GPIO_InitStruct.Pull = GPIO_NOPULL;
  GPIO_InitStruct.Speed = GPIO_SPEED_FREQ_LOW;
  GPIO_InitStruct.Alternate = GPIO_AF14_LTDC;
  HAL_GPIO_Init(GPIOK, &GPIO_InitStruct);

  /*Configure GPIO pin : LCD_B4_Pin */
  GPIO_InitStruct.Pin = LCD_B4_Pin;
  GPIO_InitStruct.Mode = GPIO_MODE_AF_PP;
  GPIO_InitStruct.Pull = GPIO_NOPULL;
  GPIO_InitStruct.Speed = GPIO_SPEED_FREQ_LOW;
  GPIO_InitStruct.Alternate = GPIO_AF9_LTDC;
  HAL_GPIO_Init(LCD_B4_GPIO_Port, &GPIO_InitStruct);

  /*Configure GPIO pin : SAI2_SDB_Pin */
  GPIO_InitStruct.Pin = SAI2_SDB_Pin;
  GPIO_InitStruct.Mode = GPIO_MODE_AF_PP;
  GPIO_InitStruct.Pull = GPIO_NOPULL;
  GPIO_InitStruct.Speed = GPIO_SPEED_FREQ_LOW;
  GPIO_InitStruct.Alternate = GPIO_AF10_SAI2;
  HAL_GPIO_Init(SAI2_SDB_GPIO_Port, &GPIO_InitStruct);

  /*Configure GPIO pin : OTG_FS_PowerSwitchOn_Pin */
  GPIO_InitStruct.Pin = OTG_FS_PowerSwitchOn_Pin;
  GPIO_InitStruct.Mode = GPIO_MODE_OUTPUT_PP;
  GPIO_InitStruct.Pull = GPIO_NOPULL;
  GPIO_InitStruct.Speed = GPIO_SPEED_FREQ_LOW;
  HAL_GPIO_Init(OTG_FS_PowerSwitchOn_GPIO_Port, &GPIO_InitStruct);

  /*Configure GPIO pin : DCMI_D5_Pin */
  GPIO_InitStruct.Pin = DCMI_D5_Pin;
  GPIO_InitStruct.Mode = GPIO_MODE_AF_PP;
  GPIO_InitStruct.Pull = GPIO_NOPULL;
  GPIO_InitStruct.Speed = GPIO_SPEED_FREQ_LOW;
  GPIO_InitStruct.Alternate = GPIO_AF13_DCMI;
  HAL_GPIO_Init(DCMI_D5_GPIO_Port, &GPIO_InitStruct);

  /*Configure GPIO pins : ARDUINO_D7_Pin ARDUINO_D8_Pin LCD_DISP_Pin */
  GPIO_InitStruct.Pin = ARDUINO_D7_Pin|ARDUINO_D8_Pin|LCD_DISP_Pin;
  GPIO_InitStruct.Mode = GPIO_MODE_OUTPUT_PP;
  GPIO_InitStruct.Pull = GPIO_NOPULL;
  GPIO_InitStruct.Speed = GPIO_SPEED_FREQ_LOW;
  HAL_GPIO_Init(GPIOI, &GPIO_InitStruct);

  /*Configure GPIO pin : uSD_Detect_Pin */
  GPIO_InitStruct.Pin = uSD_Detect_Pin;
  GPIO_InitStruct.Mode = GPIO_MODE_INPUT;
  GPIO_InitStruct.Pull = GPIO_NOPULL;
  HAL_GPIO_Init(uSD_Detect_GPIO_Port, &GPIO_InitStruct);

  /*Configure GPIO pins : LCD_HSYNC_Pin LCD_VSYNC_Pin LCD_R0_Pin LCD_CLK_Pin */
  GPIO_InitStruct.Pin = LCD_HSYNC_Pin|LCD_VSYNC_Pin|LCD_R0_Pin|LCD_CLK_Pin;
  GPIO_InitStruct.Mode = GPIO_MODE_AF_PP;
  GPIO_InitStruct.Pull = GPIO_NOPULL;
  GPIO_InitStruct.Speed = GPIO_SPEED_FREQ_LOW;
  GPIO_InitStruct.Alternate = GPIO_AF14_LTDC;
  HAL_GPIO_Init(GPIOI, &GPIO_InitStruct);

  /*Configure GPIO pin : LCD_BL_CTRL_Pin */
  GPIO_InitStruct.Pin = LCD_BL_CTRL_Pin;
  GPIO_InitStruct.Mode = GPIO_MODE_OUTPUT_PP;
  GPIO_InitStruct.Pull = GPIO_NOPULL;
  GPIO_InitStruct.Speed = GPIO_SPEED_FREQ_LOW;
  HAL_GPIO_Init(LCD_BL_CTRL_GPIO_Port, &GPIO_InitStruct);

  /*Configure GPIO pin : DCMI_VSYNC_Pin */
  GPIO_InitStruct.Pin = DCMI_VSYNC_Pin;
  GPIO_InitStruct.Mode = GPIO_MODE_AF_PP;
  GPIO_InitStruct.Pull = GPIO_NOPULL;
  GPIO_InitStruct.Speed = GPIO_SPEED_FREQ_LOW;
  GPIO_InitStruct.Alternate = GPIO_AF13_DCMI;
  HAL_GPIO_Init(DCMI_VSYNC_GPIO_Port, &GPIO_InitStruct);

  /*Configure GPIO pin : OTG_FS_OverCurrent_Pin */
  GPIO_InitStruct.Pin = OTG_FS_OverCurrent_Pin;
  GPIO_InitStruct.Mode = GPIO_MODE_INPUT;
  GPIO_InitStruct.Pull = GPIO_NOPULL;
  HAL_GPIO_Init(OTG_FS_OverCurrent_GPIO_Port, &GPIO_InitStruct);

  /*Configure GPIO pins : TP3_Pin NC2_Pin */
  GPIO_InitStruct.Pin = TP3_Pin|NC2_Pin;
  GPIO_InitStruct.Mode = GPIO_MODE_INPUT;
  GPIO_InitStruct.Pull = GPIO_NOPULL;
  HAL_GPIO_Init(GPIOH, &GPIO_InitStruct);

  /*Configure GPIO pin : ARDUINO_SCK_D13_Pin */
  GPIO_InitStruct.Pin = ARDUINO_SCK_D13_Pin;
  GPIO_InitStruct.Mode = GPIO_MODE_AF_PP;
  GPIO_InitStruct.Pull = GPIO_NOPULL;
  GPIO_InitStruct.Speed = GPIO_SPEED_FREQ_LOW;
  GPIO_InitStruct.Alternate = GPIO_AF5_SPI2;
  HAL_GPIO_Init(ARDUINO_SCK_D13_GPIO_Port, &GPIO_InitStruct);

  /*Configure GPIO pin : DCMI_PWR_EN_Pin */
  GPIO_InitStruct.Pin = DCMI_PWR_EN_Pin;
  GPIO_InitStruct.Mode = GPIO_MODE_OUTPUT_PP;
  GPIO_InitStruct.Pull = GPIO_NOPULL;
  GPIO_InitStruct.Speed = GPIO_SPEED_FREQ_LOW;
  HAL_GPIO_Init(DCMI_PWR_EN_GPIO_Port, &GPIO_InitStruct);

  /*Configure GPIO pins : DCMI_D4_Pin DCMI_D3_Pin DCMI_D0_Pin DCMI_D2_Pin
                           DCMI_D1_Pin */
  GPIO_InitStruct.Pin = DCMI_D4_Pin|DCMI_D3_Pin|DCMI_D0_Pin|DCMI_D2_Pin
                          |DCMI_D1_Pin;
  GPIO_InitStruct.Mode = GPIO_MODE_AF_PP;
  GPIO_InitStruct.Pull = GPIO_NOPULL;
  GPIO_InitStruct.Speed = GPIO_SPEED_FREQ_LOW;
  GPIO_InitStruct.Alternate = GPIO_AF13_DCMI;
  HAL_GPIO_Init(GPIOH, &GPIO_InitStruct);

  /*Configure GPIO pin : ARDUINO_PWM_CS_D5_Pin */
  GPIO_InitStruct.Pin = ARDUINO_PWM_CS_D5_Pin;
  GPIO_InitStruct.Mode = GPIO_MODE_AF_PP;
  GPIO_InitStruct.Pull = GPIO_NOPULL;
  GPIO_InitStruct.Speed = GPIO_SPEED_FREQ_LOW;
  GPIO_InitStruct.Alternate = GPIO_AF2_TIM5;
  HAL_GPIO_Init(ARDUINO_PWM_CS_D5_GPIO_Port, &GPIO_InitStruct);

  /*Configure GPIO pin : ARDUINO_PWM_D10_Pin */
  GPIO_InitStruct.Pin = ARDUINO_PWM_D10_Pin;
  GPIO_InitStruct.Mode = GPIO_MODE_AF_PP;
  GPIO_InitStruct.Pull = GPIO_NOPULL;
  GPIO_InitStruct.Speed = GPIO_SPEED_FREQ_LOW;
  GPIO_InitStruct.Alternate = GPIO_AF1_TIM1;
  HAL_GPIO_Init(ARDUINO_PWM_D10_GPIO_Port, &GPIO_InitStruct);

  /*Configure GPIO pin : LCD_INT_Pin */
  GPIO_InitStruct.Pin = LCD_INT_Pin;
  GPIO_InitStruct.Mode = GPIO_MODE_EVT_RISING;
  GPIO_InitStruct.Pull = GPIO_NOPULL;
  HAL_GPIO_Init(LCD_INT_GPIO_Port, &GPIO_InitStruct);

  /*Configure GPIO pins : ARDUINO_RX_D0_Pin ARDUINO_TX_D1_Pin */
  GPIO_InitStruct.Pin = ARDUINO_RX_D0_Pin|ARDUINO_TX_D1_Pin;
  GPIO_InitStruct.Mode = GPIO_MODE_AF_PP;
  GPIO_InitStruct.Pull = GPIO_NOPULL;
  GPIO_InitStruct.Speed = GPIO_SPEED_FREQ_VERY_HIGH;
  GPIO_InitStruct.Alternate = GPIO_AF8_USART6;
  HAL_GPIO_Init(GPIOC, &GPIO_InitStruct);

  /*Configure GPIO pins : ARDUINO_D4_Pin ARDUINO_D2_Pin EXT_RST_Pin */
  GPIO_InitStruct.Pin = ARDUINO_D4_Pin|ARDUINO_D2_Pin|EXT_RST_Pin;
  GPIO_InitStruct.Mode = GPIO_MODE_OUTPUT_PP;
  GPIO_InitStruct.Pull = GPIO_NOPULL;
  GPIO_InitStruct.Speed = GPIO_SPEED_FREQ_LOW;
  HAL_GPIO_Init(GPIOG, &GPIO_InitStruct);

  /*Configure GPIO pins : ARDUINO_A4_Pin ARDUINO_A5_Pin ARDUINO_A1_Pin ARDUINO_A2_Pin
                           ARDUINO_A3_Pin */
  GPIO_InitStruct.Pin = ARDUINO_A4_Pin|ARDUINO_A5_Pin|ARDUINO_A1_Pin|ARDUINO_A2_Pin
                          |ARDUINO_A3_Pin;
  GPIO_InitStruct.Mode = GPIO_MODE_ANALOG;
  GPIO_InitStruct.Pull = GPIO_NOPULL;
  HAL_GPIO_Init(GPIOF, &GPIO_InitStruct);

  /*Configure GPIO pin : RMII_RXER_Pin */
  GPIO_InitStruct.Pin = RMII_RXER_Pin;
  GPIO_InitStruct.Mode = GPIO_MODE_INPUT;
  GPIO_InitStruct.Pull = GPIO_NOPULL;
  HAL_GPIO_Init(RMII_RXER_GPIO_Port, &GPIO_InitStruct);

  /*Configure GPIO pin : ARDUINO_A0_Pin */
  GPIO_InitStruct.Pin = ARDUINO_A0_Pin;
  GPIO_InitStruct.Mode = GPIO_MODE_ANALOG;
  GPIO_InitStruct.Pull = GPIO_NOPULL;
  HAL_GPIO_Init(ARDUINO_A0_GPIO_Port, &GPIO_InitStruct);

  /*Configure GPIO pins : DCMI_HSYNC_Pin PA6 */
  GPIO_InitStruct.Pin = DCMI_HSYNC_Pin|GPIO_PIN_6;
  GPIO_InitStruct.Mode = GPIO_MODE_AF_PP;
  GPIO_InitStruct.Pull = GPIO_NOPULL;
  GPIO_InitStruct.Speed = GPIO_SPEED_FREQ_LOW;
  GPIO_InitStruct.Alternate = GPIO_AF13_DCMI;
  HAL_GPIO_Init(GPIOA, &GPIO_InitStruct);

  /*Configure GPIO pin : ARDUINO_PWM_D6_Pin */
  GPIO_InitStruct.Pin = ARDUINO_PWM_D6_Pin;
  GPIO_InitStruct.Mode = GPIO_MODE_AF_PP;
  GPIO_InitStruct.Pull = GPIO_NOPULL;
  GPIO_InitStruct.Speed = GPIO_SPEED_FREQ_LOW;
  GPIO_InitStruct.Alternate = GPIO_AF9_TIM12;
  HAL_GPIO_Init(ARDUINO_PWM_D6_GPIO_Port, &GPIO_InitStruct);

  /*Configure GPIO pins : ARDUINO_MISO_D12_Pin ARDUINO_MOSI_PWM_D11_Pin */
  GPIO_InitStruct.Pin = ARDUINO_MISO_D12_Pin|ARDUINO_MOSI_PWM_D11_Pin;
  GPIO_InitStruct.Mode = GPIO_MODE_AF_PP;
  GPIO_InitStruct.Pull = GPIO_NOPULL;
  GPIO_InitStruct.Speed = GPIO_SPEED_FREQ_LOW;
  GPIO_InitStruct.Alternate = GPIO_AF5_SPI2;
  HAL_GPIO_Init(GPIOB, &GPIO_InitStruct);

}

void StartDefaultTask(void const * argument)
{
  /* init code for USB_HOST */
  MX_USB_HOST_Init();

  /* init code for LWIP */
  MX_LWIP_Init();

  /* init code for USB_DEVICE */
  MX_USB_DEVICE_Init();
  /* USER CODE BEGIN 5 */
	BSP_Config();
	osDelay(100);
	TS_Init();
	osDelay(100);
	QSPI_Init();

	httpd_init();

  for(;;)
  {
	  ethernetif_input(&gnetif);
	  sys_check_timeouts();

	  BSP_TS_GetState(&TS_State);
	  if(TS_State.touchDetected && !HoldTouch)
	  {
		HoldTouch = true;
	  	//ReactOnTouch();
	  }
	  else if(!TS_State.touchDetected && HoldTouch)
	  {
		  ReactOnTouch();
		  HoldTouch = false;
	  }

    osDelay(1);
  }
  /* USER CODE END 5 */
}

/* MPU Configuration */

void MPU_Config(void)
{
  MPU_Region_InitTypeDef MPU_InitStruct = {0};

  /* Disables the MPU */
  HAL_MPU_Disable();
  /** Initializes and configures the Region and the memory to be protected
  */
  MPU_InitStruct.Enable = MPU_REGION_ENABLE;
  MPU_InitStruct.Number = MPU_REGION_NUMBER0;
  MPU_InitStruct.BaseAddress = 0x90000000;
  MPU_InitStruct.Size = MPU_REGION_SIZE_256MB;
  MPU_InitStruct.SubRegionDisable = 0x0;
  MPU_InitStruct.TypeExtField = MPU_TEX_LEVEL0;
  MPU_InitStruct.AccessPermission = MPU_REGION_FULL_ACCESS;
  MPU_InitStruct.DisableExec = MPU_INSTRUCTION_ACCESS_ENABLE;
  MPU_InitStruct.IsShareable = MPU_ACCESS_NOT_SHAREABLE;
  MPU_InitStruct.IsCacheable = MPU_ACCESS_NOT_CACHEABLE;
  MPU_InitStruct.IsBufferable = MPU_ACCESS_NOT_BUFFERABLE;

  HAL_MPU_ConfigRegion(&MPU_InitStruct);
  /** Initializes and configures the Region and the memory to be protected
  */
  MPU_InitStruct.Number = MPU_REGION_NUMBER1;
  MPU_InitStruct.Size = MPU_REGION_SIZE_16MB;
  MPU_InitStruct.IsCacheable = MPU_ACCESS_CACHEABLE;

  HAL_MPU_ConfigRegion(&MPU_InitStruct);
  /* Enables the MPU */
  HAL_MPU_Enable(MPU_PRIVILEGED_DEFAULT);

}

void HAL_TIM_PeriodElapsedCallback(TIM_HandleTypeDef *htim)
{
  if (htim->Instance == TIM6) {
    HAL_IncTick();
  }
}

void Error_Handler(void)
{
}

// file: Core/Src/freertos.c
/* USER CODE BEGIN Header */
/**
  ******************************************************************************
  * File Name          : freertos.c
  * Description        : Code for freertos applications
  ******************************************************************************
  * @attention
  *
  * Copyright (c) 2021 STMicroelectronics.
  * All rights reserved.
  *
  * This software is licensed under terms that can be found in the LICENSE file
  * in the root directory of this software component.
  * If no LICENSE file comes with this software, it is provided AS-IS.
  *
  ******************************************************************************
  */
/* USER CODE END Header */

#include "FreeRTOS.h"
#include "task.h"
#include "main.h"

/* GetIdleTaskMemory prototype (linked to static allocation support) */
void vApplicationGetIdleTaskMemory( StaticTask_t **ppxIdleTaskTCBBuffer, StackType_t **ppxIdleTaskStackBuffer, uint32_t *pulIdleTaskStackSize );

/* Hook prototypes */
void vApplicationIdleHook(void);
void vApplicationStackOverflowHook(xTaskHandle xTask, signed char *pcTaskName);
void vApplicationMallocFailedHook(void);

/* USER CODE BEGIN 2 */
__weak void vApplicationIdleHook( void )
{
   /* vApplicationIdleHook() will only be called if configUSE_IDLE_HOOK is set
   to 1 in FreeRTOSConfig.h. It will be called on each iteration of the idle
   task. It is essential that code added to this hook function never attempts
   to block in any way (for example, call xQueueReceive() with a block time
   specified, or call vTaskDelay()). If the application makes use of the
   vTaskDelete() API function (as this demo application does) then it is also
   important that vApplicationIdleHook() is permitted to return to its calling
   function, because it is the responsibility of the idle task to clean up
   memory allocated by the kernel to any task that has since been deleted. */
}
/* USER CODE END 2 */

/* USER CODE BEGIN 4 */
__weak void vApplicationStackOverflowHook(xTaskHandle xTask, signed char *pcTaskName)
{
   /* Run time stack overflow checking is performed if
   configCHECK_FOR_STACK_OVERFLOW is defined to 1 or 2. This hook function is
   called if a stack overflow is detected. */
}
/* USER CODE END 4 */

/* USER CODE BEGIN 5 */
__weak void vApplicationMallocFailedHook(void)
{
   /* vApplicationMallocFailedHook() will only be called if
   configUSE_MALLOC_FAILED_HOOK is set to 1 in FreeRTOSConfig.h. It is a hook
   function that will get called if a call to pvPortMalloc() fails.
   pvPortMalloc() is called internally by the kernel whenever a task, queue,
   timer or semaphore is created. It is also called by various parts of the
   demo application. If heap_1.c or heap_2.c are used, then the size of the
   heap available to pvPortMalloc() is defined by configTOTAL_HEAP_SIZE in
   FreeRTOSConfig.h, and the xPortGetFreeHeapSize() API function can be used
   to query the size of free heap space that remains (although it does not
   provide information on how the remaining heap might be fragmented). */
}
/* USER CODE END 5 */

/* USER CODE BEGIN GET_IDLE_TASK_MEMORY */
static StaticTask_t xIdleTaskTCBBuffer;
static StackType_t xIdleStack[configMINIMAL_STACK_SIZE];

void vApplicationGetIdleTaskMemory( StaticTask_t **ppxIdleTaskTCBBuffer, StackType_t **ppxIdleTaskStackBuffer, uint32_t *pulIdleTaskStackSize )
{
  *ppxIdleTaskTCBBuffer = &xIdleTaskTCBBuffer;
  *ppxIdleTaskStackBuffer = &xIdleStack[0];
  *pulIdleTaskStackSize = configMINIMAL_STACK_SIZE;
  /* place for user code */
}
/* USER CODE END GET_IDLE_TASK_MEMORY */
